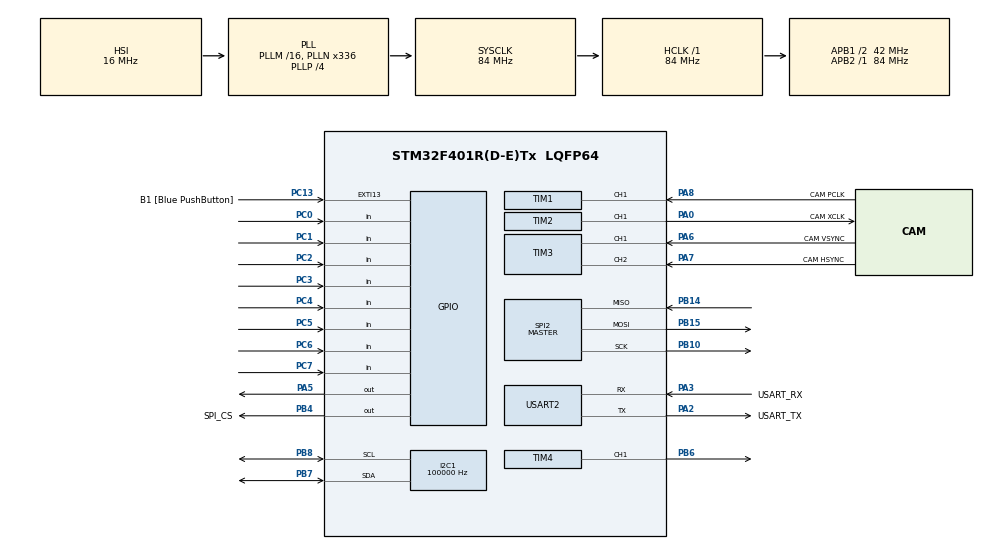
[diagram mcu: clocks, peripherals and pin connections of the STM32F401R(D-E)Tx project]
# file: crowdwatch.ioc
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Mcu.Family=STM32F4
PA2.GPIO_PuPd=GPIO_NOPULL
RCC.CortexFreq_Value=84000000
SPI2.VirtualType=VM_MASTER
PB10.Mode=Full_Duplex_Master
PA14.GPIO_Label=TCK
PA3.GPIO_PuPd=GPIO_NOPULL
PA2.GPIO_Speed=GPIO_SPEED_FREQ_LOW
Dma.TIM1_CH1.0.MemDataAlignment=DMA_MDATAALIGN_BYTE
PA6.GPIO_Label=CAM VSYNC
PA3.GPIO_Speed=GPIO_SPEED_FREQ_LOW
PB15.Signal=SPI2_MOSI
RCC.SYSCLKSource=RCC_SYSCLKSOURCE_PLLCLK
ProjectManager.StackSize=0x400
Dma.TIM1_CH1.0.MemInc=DMA_MINC_ENABLE
VP_TIM1_VS_ControllerModeReset.Mode=Reset Mode
PH0\ -\ OSC_IN.Signal=RCC_OSC_IN
I2C1.ClockSpeed=100000
RCC.HCLKFreq_Value=84000000
RCC.APB2TimFreq_Value=84000000
PB6.Signal=S_TIM4_CH1
PC7.Signal=GPIO_Input
PC3.Signal=GPIO_Input
VP_TIM3_VS_ControllerModeClock.Mode=Clock Mode
RCC.AHBFreq_Value=84000000
SPI2.BaudRatePrescaler=SPI_BAUDRATEPRESCALER_128
RCC.HSE_VALUE=8000000
TIM3.Channel-Input_Capture1_from_TI1=TIM_CHANNEL_1
PC13-ANTI_TAMP.Signal=GPXTI13
PC14-OSC32_IN.Mode=LSE-External-Oscillator
PA14.Mode=Serial_Wire
PB14.Mode=Full_Duplex_Master
PB7.Signal=I2C1_SDA
PA8.Signal=S_TIM1_CH1
TIM2.Channel-PWM\ Generation1\ CH1=TIM_CHANNEL_1
SH.S_TIM3_CH1.0=TIM3_CH1,Input_Capture1_from_TI1
TIM4.Period=255
VP_TIM3_VS_ClockSourceITR.Mode=TriggerSource_ITR0
Dma.TIM1_CH1.0.FIFOThreshold=DMA_FIFO_THRESHOLD_FULL
VP_TIM1_VS_ClockSourceINT.Mode=Internal
Mcu.Package=LQFP64
PA6.Signal=S_TIM3_CH1
SPI2.Mode=SPI_MODE_MASTER
USART2.VirtualMode=VM_ASYNC
PA2.GPIO_Label=USART_TX
SH.S_TIM4_CH1.0=TIM4_CH1,PWM Generation1 CH1
RCC.APB1TimFreq_Value=84000000
SPI2.Direction=SPI_DIRECTION_2LINES
PC5.Signal=GPIO_Input
Dma.Request0=TIM1_CH1
PB4.Signal=GPIO_Output
PA3.Signal=USART2_RX
PA2.GPIO_Mode=GPIO_MODE_AF_PP
PB3.GPIO_Label=SWO
TIM4.Channel-PWM\ Generation1\ CH1=TIM_CHANNEL_1
PC15-OSC32_OUT.Mode=LSE-External-Oscillator
TIM3.Channel-Input_Capture2_from_TI2=TIM_CHANNEL_2
PC13-ANTI_TAMP.GPIO_PuPd=GPIO_NOPULL
PC13-ANTI_TAMP.GPIO_Label=B1 [Blue PushButton]
PH1\ -\ OSC_OUT.Mode=HSE-External-Clock-Source
PC2.Signal=GPIO_Input
PC4.Signal=GPIO_Input
PC6.Signal=GPIO_Input
Dma.TIM1_CH1.0.FIFOMode=DMA_FIFOMODE_ENABLE
NVIC.DMA2_Stream1_IRQn=true\:0\:0\:false\:false\:true\:false\:true
PC0.Signal=GPIO_Input
RCC.APB1CLKDivider=RCC_HCLK_DIV2
PC14-OSC32_IN.Signal=RCC_OSC32_IN
Dma.TIM1_CH1.0.PeriphDataAlignment=DMA_PDATAALIGN_BYTE
Dma.TIM1_CH1.0.Priority=DMA_PRIORITY_VERY_HIGH
PA0-WKUP.GPIO_Label=CAM XCLK
PA0-WKUP.Signal=S_TIM2_CH1_ETR
TIM2.Pulse-PWM\ Generation1\ CH1=4
Dma.TIM1_CH1.0.PeriphInc=DMA_PINC_DISABLE
PA3.Mode=Asynchronous
PA13.Signal=SYS_JTMS-SWDIO
PH0\ -\ OSC_IN.Mode=HSE-External-Clock-Source
Dma.TIM1_CH1.0.Mode=DMA_CIRCULAR
PA8.GPIO_Label=CAM PCLK
SH.S_TIM1_CH1.0=TIM1_CH1,TriggerSource_TI1FP1
SH.S_TIM1_CH1.1=TIM1_CH1,Input_Capture1_from_TI1
ProjectManager.TargetToolchain=STM32CubeIDE
Dma.TIM1_CH1.0.PeriphBurst=DMA_PBURST_SINGLE
I2C1.I2C_Mode=I2C_Standard
PA3.GPIO_Mode=GPIO_MODE_AF_PP
PC15-OSC32_OUT.Signal=RCC_OSC32_OUT
PB10.Signal=SPI2_SCK
PB14.Signal=SPI2_MISO
PA5.Signal=GPIO_Output
SH.S_TIM3_CH2.0=TIM3_CH2,Input_Capture2_from_TI2
PH1\ -\ OSC_OUT.Signal=RCC_OSC_OUT
board=NUCLEO-F401RE
RCC.VCOOutputFreq_Value=336000000
PB15.Mode=Full_Duplex_Master
NVIC.TIM3_IRQn=true\:0\:0\:false\:false\:true\:true\:true
RCC.APB2Freq_Value=84000000
PB4.GPIO_Label=SPI_CS
TIM3.ICPolarity_CH2=TIM_INPUTCHANNELPOLARITY_FALLING
TIM3.ICPolarity_CH1=TIM_INPUTCHANNELPOLARITY_BOTHEDGE
TIM2.Period=7
PA13.Mode=Serial_Wire
Mcu.Name=STM32F401R(D-E)Tx
PA2.Signal=USART2_TX
PA13.GPIO_Label=TMS
Dma.TIM1_CH1.0.Direction=DMA_PERIPH_TO_MEMORY
RCC.48MHZClocksFreq_Value=48000000
PB3.Signal=SYS_JTDO-SWO
RCC.SYSCLKFreq_VALUE=84000000
Dma.TIM1_CH1.0.Instance=DMA2_Stream1
PA7.GPIO_Label=CAM HSYNC
TIM1.Channel-Input_Capture1_from_TI1=TIM_CHANNEL_1
PC13-ANTI_TAMP.GPIO_ModeDefaultEXTI=GPIO_MODE_IT_FALLING
Dma.TIM1_CH1.0.MemBurst=DMA_MBURST_INC16
PB7.Mode=I2C
SH.S_TIM2_CH1_ETR.0=TIM2_CH1,PWM Generation1 CH1
PA14.Signal=SYS_JTCK-SWCLK
ProjectManager.HeapSize=0x200
RCC.HSI_VALUE=16000000
VP_TIM4_VS_ClockSourceINT.Mode=Internal
RCC.PLLP=RCC_PLLP_DIV4
RCC.PLLQ=7
NVIC.PriorityGroup=NVIC_PRIORITYGROUP_0
PB8.Mode=I2C
RCC.PLLN=336
PA2.Mode=Asynchronous
PB8.Signal=I2C1_SCL
RCC.APB1Freq_Value=42000000
PC1.Signal=GPIO_Input
TIM1.TIM_MasterSlaveMode=TIM_MASTERSLAVEMODE_ENABLE
PA3.GPIO_Label=USART_RX
PA7.Signal=S_TIM3_CH2

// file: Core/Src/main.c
/* USER CODE BEGIN Header */
/**
  ******************************************************************************
  * @file           : main.c
  * @brief          : Main program body
  ******************************************************************************
  * @attention
  *
  * <h2><center>&copy; Copyright (c) 2021 STMicroelectronics.
  * All rights reserved.</center></h2>
  *
  * This software component is licensed by ST under BSD 3-Clause license,
  * the "License"; You may not use this file except in compliance with the
  * License. You may obtain a copy of the License at:
  *                        opensource.org/licenses/BSD-3-Clause
  *
  ******************************************************************************
  */
/* USER CODE END Header */
#include "main.h"

/* USER CODE BEGIN Includes */

#include "cwsys/cwsys.h"

/* USER CODE END Includes */

I2C_HandleTypeDef hi2c1;

SPI_HandleTypeDef hspi2;

TIM_HandleTypeDef htim1;
TIM_HandleTypeDef htim2;
TIM_HandleTypeDef htim3;
TIM_HandleTypeDef htim4;
DMA_HandleTypeDef hdma_tim1_ch1;

UART_HandleTypeDef huart2;

void SystemClock_Config(void);
static void MX_GPIO_Init(void);
static void MX_DMA_Init(void);
static void MX_USART2_UART_Init(void);
static void MX_I2C1_Init(void);
static void MX_TIM1_Init(void);
static void MX_TIM2_Init(void);
static void MX_TIM3_Init(void);
static void MX_SPI2_Init(void);
static void MX_TIM4_Init(void);

int main(void)
{

  /* MCU Configuration--------------------------------------------------------*/

  /* Reset of all peripherals, Initializes the Flash interface and the Systick. */
  HAL_Init();

  /* Configure the system clock */
  SystemClock_Config();

  /* Initialize all configured peripherals */
  MX_GPIO_Init();
  MX_DMA_Init();
  MX_USART2_UART_Init();
  MX_I2C1_Init();
  MX_TIM1_Init();
  MX_TIM2_Init();
  MX_TIM3_Init();
  MX_SPI2_Init();
  MX_TIM4_Init();
  /* USER CODE BEGIN 2 */

  // Configure and run CrowdWatch
  struct cwsys_init_params cwsys_param = {
		  .infoSerial = &huart2,
		  .cameraParams = {
				  .tim1Sync = &htim1,
				  .tim3Sync = &htim3,
				  .camClkPwm = &htim2,
				  .pixdma = &hdma_tim1_ch1,
				  .pixDataGPIOIdr = &GPIOC->IDR,
				  .sccb = &hi2c1,
		  },
		  .espSpi = &hspi2,
  };
  cwsys(cwsys_param);
  /* USER CODE END 2 */

  /* Infinite loop */
  while (1)
  {

  }
}

void SystemClock_Config(void)
{
  RCC_OscInitTypeDef RCC_OscInitStruct = {0};
  RCC_ClkInitTypeDef RCC_ClkInitStruct = {0};

  /** Configure the main internal regulator output voltage
  */
  __HAL_RCC_PWR_CLK_ENABLE();
  __HAL_PWR_VOLTAGESCALING_CONFIG(PWR_REGULATOR_VOLTAGE_SCALE2);
  /** Initializes the RCC Oscillators according to the specified parameters
  * in the RCC_OscInitTypeDef structure.
  */
  RCC_OscInitStruct.OscillatorType = RCC_OSCILLATORTYPE_HSI;
  RCC_OscInitStruct.HSIState = RCC_HSI_ON;
  RCC_OscInitStruct.HSICalibrationValue = RCC_HSICALIBRATION_DEFAULT;
  RCC_OscInitStruct.PLL.PLLState = RCC_PLL_ON;
  RCC_OscInitStruct.PLL.PLLSource = RCC_PLLSOURCE_HSI;
  RCC_OscInitStruct.PLL.PLLM = 16;
  RCC_OscInitStruct.PLL.PLLN = 336;
  RCC_OscInitStruct.PLL.PLLP = RCC_PLLP_DIV4;
  RCC_OscInitStruct.PLL.PLLQ = 7;
  if (HAL_RCC_OscConfig(&RCC_OscInitStruct) != HAL_OK)
  {
    Error_Handler();
  }
  /** Initializes the CPU, AHB and APB buses clocks
  */
  RCC_ClkInitStruct.ClockType = RCC_CLOCKTYPE_HCLK|RCC_CLOCKTYPE_SYSCLK
                              |RCC_CLOCKTYPE_PCLK1|RCC_CLOCKTYPE_PCLK2;
  RCC_ClkInitStruct.SYSCLKSource = RCC_SYSCLKSOURCE_PLLCLK;
  RCC_ClkInitStruct.AHBCLKDivider = RCC_SYSCLK_DIV1;
  RCC_ClkInitStruct.APB1CLKDivider = RCC_HCLK_DIV2;
  RCC_ClkInitStruct.APB2CLKDivider = RCC_HCLK_DIV1;

  if (HAL_RCC_ClockConfig(&RCC_ClkInitStruct, FLASH_LATENCY_2) != HAL_OK)
  {
    Error_Handler();
  }
}

static void MX_I2C1_Init(void)
{

  hi2c1.Instance = I2C1;
  hi2c1.Init.ClockSpeed = 100000;
  hi2c1.Init.DutyCycle = I2C_DUTYCYCLE_2;
  hi2c1.Init.OwnAddress1 = 0;
  hi2c1.Init.AddressingMode = I2C_ADDRESSINGMODE_7BIT;
  hi2c1.Init.DualAddressMode = I2C_DUALADDRESS_DISABLE;
  hi2c1.Init.OwnAddress2 = 0;
  hi2c1.Init.GeneralCallMode = I2C_GENERALCALL_DISABLE;
  hi2c1.Init.NoStretchMode = I2C_NOSTRETCH_DISABLE;
  if (HAL_I2C_Init(&hi2c1) != HAL_OK)
  {
    Error_Handler();
  }

}

static void MX_SPI2_Init(void)
{

  /* SPI2 parameter configuration*/
  hspi2.Instance = SPI2;
  hspi2.Init.Mode = SPI_MODE_MASTER;
  hspi2.Init.Direction = SPI_DIRECTION_2LINES;
  hspi2.Init.DataSize = SPI_DATASIZE_8BIT;
  hspi2.Init.CLKPolarity = SPI_POLARITY_LOW;
  hspi2.Init.CLKPhase = SPI_PHASE_1EDGE;
  hspi2.Init.NSS = SPI_NSS_SOFT;
  hspi2.Init.BaudRatePrescaler = SPI_BAUDRATEPRESCALER_256;
  hspi2.Init.FirstBit = SPI_FIRSTBIT_MSB;
  hspi2.Init.TIMode = SPI_TIMODE_DISABLE;
  hspi2.Init.CRCCalculation = SPI_CRCCALCULATION_DISABLE;
  hspi2.Init.CRCPolynomial = 10;
  if (HAL_SPI_Init(&hspi2) != HAL_OK)
  {
    Error_Handler();
  }

}

static void MX_TIM1_Init(void)
{

  TIM_ClockConfigTypeDef sClockSourceConfig = {0};
  TIM_SlaveConfigTypeDef sSlaveConfig = {0};
  TIM_MasterConfigTypeDef sMasterConfig = {0};
  TIM_IC_InitTypeDef sConfigIC = {0};

  htim1.Instance = TIM1;
  htim1.Init.Prescaler = 0;
  htim1.Init.CounterMode = TIM_COUNTERMODE_UP;
  htim1.Init.Period = 65535;
  htim1.Init.ClockDivision = TIM_CLOCKDIVISION_DIV1;
  htim1.Init.RepetitionCounter = 0;
  htim1.Init.AutoReloadPreload = TIM_AUTORELOAD_PRELOAD_DISABLE;
  if (HAL_TIM_Base_Init(&htim1) != HAL_OK)
  {
    Error_Handler();
  }
  sClockSourceConfig.ClockSource = TIM_CLOCKSOURCE_INTERNAL;
  if (HAL_TIM_ConfigClockSource(&htim1, &sClockSourceConfig) != HAL_OK)
  {
    Error_Handler();
  }
  if (HAL_TIM_IC_Init(&htim1) != HAL_OK)
  {
    Error_Handler();
  }
  sSlaveConfig.SlaveMode = TIM_SLAVEMODE_RESET;
  sSlaveConfig.InputTrigger = TIM_TS_TI1FP1;
  sSlaveConfig.TriggerPolarity = TIM_INPUTCHANNELPOLARITY_RISING;
  sSlaveConfig.TriggerFilter = 0;
  if (HAL_TIM_SlaveConfigSynchro(&htim1, &sSlaveConfig) != HAL_OK)
  {
    Error_Handler();
  }
  sMasterConfig.MasterOutputTrigger = TIM_TRGO_RESET;
  sMasterConfig.MasterSlaveMode = TIM_MASTERSLAVEMODE_ENABLE;
  if (HAL_TIMEx_MasterConfigSynchronization(&htim1, &sMasterConfig) != HAL_OK)
  {
    Error_Handler();
  }
  sConfigIC.ICPolarity = TIM_INPUTCHANNELPOLARITY_RISING;
  sConfigIC.ICSelection = TIM_ICSELECTION_DIRECTTI;
  sConfigIC.ICPrescaler = TIM_ICPSC_DIV1;
  sConfigIC.ICFilter = 0;
  if (HAL_TIM_IC_ConfigChannel(&htim1, &sConfigIC, TIM_CHANNEL_1) != HAL_OK)
  {
    Error_Handler();
  }

}

static void MX_TIM2_Init(void)
{

  TIM_MasterConfigTypeDef sMasterConfig = {0};
  TIM_OC_InitTypeDef sConfigOC = {0};

  htim2.Instance = TIM2;
  htim2.Init.Prescaler = 0;
  htim2.Init.CounterMode = TIM_COUNTERMODE_UP;
  htim2.Init.Period = 7;
  htim2.Init.ClockDivision = TIM_CLOCKDIVISION_DIV1;
  htim2.Init.AutoReloadPreload = TIM_AUTORELOAD_PRELOAD_DISABLE;
  if (HAL_TIM_PWM_Init(&htim2) != HAL_OK)
  {
    Error_Handler();
  }
  sMasterConfig.MasterOutputTrigger = TIM_TRGO_RESET;
  sMasterConfig.MasterSlaveMode = TIM_MASTERSLAVEMODE_DISABLE;
  if (HAL_TIMEx_MasterConfigSynchronization(&htim2, &sMasterConfig) != HAL_OK)
  {
    Error_Handler();
  }
  sConfigOC.OCMode = TIM_OCMODE_PWM1;
  sConfigOC.Pulse = 4;
  sConfigOC.OCPolarity = TIM_OCPOLARITY_HIGH;
  sConfigOC.OCFastMode = TIM_OCFAST_DISABLE;
  if (HAL_TIM_PWM_ConfigChannel(&htim2, &sConfigOC, TIM_CHANNEL_1) != HAL_OK)
  {
    Error_Handler();
  }
  HAL_TIM_MspPostInit(&htim2);

}

static void MX_TIM3_Init(void)
{

  TIM_SlaveConfigTypeDef sSlaveConfig = {0};
  TIM_MasterConfigTypeDef sMasterConfig = {0};
  TIM_IC_InitTypeDef sConfigIC = {0};

  htim3.Instance = TIM3;
  htim3.Init.Prescaler = 0;
  htim3.Init.CounterMode = TIM_COUNTERMODE_UP;
  htim3.Init.Period = 65535;
  htim3.Init.ClockDivision = TIM_CLOCKDIVISION_DIV1;
  htim3.Init.AutoReloadPreload = TIM_AUTORELOAD_PRELOAD_DISABLE;
  if (HAL_TIM_Base_Init(&htim3) != HAL_OK)
  {
    Error_Handler();
  }
  if (HAL_TIM_IC_Init(&htim3) != HAL_OK)
  {
    Error_Handler();
  }
  sSlaveConfig.SlaveMode = TIM_SLAVEMODE_EXTERNAL1;
  sSlaveConfig.InputTrigger = TIM_TS_ITR0;
  if (HAL_TIM_SlaveConfigSynchro(&htim3, &sSlaveConfig) != HAL_OK)
  {
    Error_Handler();
  }
  sMasterConfig.MasterOutputTrigger = TIM_TRGO_RESET;
  sMasterConfig.MasterSlaveMode = TIM_MASTERSLAVEMODE_DISABLE;
  if (HAL_TIMEx_MasterConfigSynchronization(&htim3, &sMasterConfig) != HAL_OK)
  {
    Error_Handler();
  }
  sConfigIC.ICPolarity = TIM_INPUTCHANNELPOLARITY_BOTHEDGE;
  sConfigIC.ICSelection = TIM_ICSELECTION_DIRECTTI;
  sConfigIC.ICPrescaler = TIM_ICPSC_DIV1;
  sConfigIC.ICFilter = 0;
  if (HAL_TIM_IC_ConfigChannel(&htim3, &sConfigIC, TIM_CHANNEL_1) != HAL_OK)
  {
    Error_Handler();
  }
  sConfigIC.ICPolarity = TIM_INPUTCHANNELPOLARITY_FALLING;
  if (HAL_TIM_IC_ConfigChannel(&htim3, &sConfigIC, TIM_CHANNEL_2) != HAL_OK)
  {
    Error_Handler();
  }

}

static void MX_TIM4_Init(void)
{

  TIM_ClockConfigTypeDef sClockSourceConfig = {0};
  TIM_MasterConfigTypeDef sMasterConfig = {0};
  TIM_OC_InitTypeDef sConfigOC = {0};

  htim4.Instance = TIM4;
  htim4.Init.Prescaler = 0;
  htim4.Init.CounterMode = TIM_COUNTERMODE_UP;
  htim4.Init.Period = 255;
  htim4.Init.ClockDivision = TIM_CLOCKDIVISION_DIV1;
  htim4.Init.AutoReloadPreload = TIM_AUTORELOAD_PRELOAD_DISABLE;
  if (HAL_TIM_Base_Init(&htim4) != HAL_OK)
  {
    Error_Handler();
  }
  sClockSourceConfig.ClockSource = TIM_CLOCKSOURCE_INTERNAL;
  if (HAL_TIM_ConfigClockSource(&htim4, &sClockSourceConfig) != HAL_OK)
  {
    Error_Handler();
  }
  if (HAL_TIM_PWM_Init(&htim4) != HAL_OK)
  {
    Error_Handler();
  }
  sMasterConfig.MasterOutputTrigger = TIM_TRGO_RESET;
  sMasterConfig.MasterSlaveMode = TIM_MASTERSLAVEMODE_DISABLE;
  if (HAL_TIMEx_MasterConfigSynchronization(&htim4, &sMasterConfig) != HAL_OK)
  {
    Error_Handler();
  }
  sConfigOC.OCMode = TIM_OCMODE_PWM1;
  sConfigOC.Pulse = 0;
  sConfigOC.OCPolarity = TIM_OCPOLARITY_HIGH;
  sConfigOC.OCFastMode = TIM_OCFAST_DISABLE;
  if (HAL_TIM_PWM_ConfigChannel(&htim4, &sConfigOC, TIM_CHANNEL_1) != HAL_OK)
  {
    Error_Handler();
  }
  HAL_TIM_MspPostInit(&htim4);

}

static void MX_USART2_UART_Init(void)
{

  huart2.Instance = USART2;
  huart2.Init.BaudRate = 115200;
  huart2.Init.WordLength = UART_WORDLENGTH_8B;
  huart2.Init.StopBits = UART_STOPBITS_1;
  huart2.Init.Parity = UART_PARITY_NONE;
  huart2.Init.Mode = UART_MODE_TX_RX;
  huart2.Init.HwFlowCtl = UART_HWCONTROL_NONE;
  huart2.Init.OverSampling = UART_OVERSAMPLING_16;
  if (HAL_UART_Init(&huart2) != HAL_OK)
  {
    Error_Handler();
  }

}

static void MX_DMA_Init(void)
{

  /* DMA controller clock enable */
  __HAL_RCC_DMA2_CLK_ENABLE();

  /* DMA interrupt init */
  /* DMA2_Stream1_IRQn interrupt configuration */
  HAL_NVIC_SetPriority(DMA2_Stream1_IRQn, 0, 0);
  HAL_NVIC_EnableIRQ(DMA2_Stream1_IRQn);

}

static void MX_GPIO_Init(void)
{
  GPIO_InitTypeDef GPIO_InitStruct = {0};

  /* GPIO Ports Clock Enable */
  __HAL_RCC_GPIOC_CLK_ENABLE();
  __HAL_RCC_GPIOH_CLK_ENABLE();
  __HAL_RCC_GPIOA_CLK_ENABLE();
  __HAL_RCC_GPIOB_CLK_ENABLE();

  /*Configure GPIO pin Output Level */
  HAL_GPIO_WritePin(GPIOA, GPIO_PIN_5, GPIO_PIN_RESET);

  /*Configure GPIO pin Output Level */
  HAL_GPIO_WritePin(SPI_CS_GPIO_Port, SPI_CS_Pin, GPIO_PIN_RESET);

  /*Configure GPIO pin : B1_Pin */
  GPIO_InitStruct.Pin = B1_Pin;
  GPIO_InitStruct.Mode = GPIO_MODE_IT_FALLING;
  GPIO_InitStruct.Pull = GPIO_NOPULL;
  HAL_GPIO_Init(B1_GPIO_Port, &GPIO_InitStruct);

  /*Configure GPIO pins : PC0 PC1 PC2 PC3
                           PC4 PC5 PC6 PC7 */
  GPIO_InitStruct.Pin = GPIO_PIN_0|GPIO_PIN_1|GPIO_PIN_2|GPIO_PIN_3
                          |GPIO_PIN_4|GPIO_PIN_5|GPIO_PIN_6|GPIO_PIN_7;
  GPIO_InitStruct.Mode = GPIO_MODE_INPUT;
  GPIO_InitStruct.Pull = GPIO_NOPULL;
  HAL_GPIO_Init(GPIOC, &GPIO_InitStruct);

  /*Configure GPIO pin : PA5 */
  GPIO_InitStruct.Pin = GPIO_PIN_5;
  GPIO_InitStruct.Mode = GPIO_MODE_OUTPUT_PP;
  GPIO_InitStruct.Pull = GPIO_NOPULL;
  GPIO_InitStruct.Speed = GPIO_SPEED_FREQ_LOW;
  HAL_GPIO_Init(GPIOA, &GPIO_InitStruct);

  /*Configure GPIO pin : SPI_CS_Pin */
  GPIO_InitStruct.Pin = SPI_CS_Pin;
  GPIO_InitStruct.Mode = GPIO_MODE_OUTPUT_PP;
  GPIO_InitStruct.Pull = GPIO_NOPULL;
  GPIO_InitStruct.Speed = GPIO_SPEED_FREQ_LOW;
  HAL_GPIO_Init(SPI_CS_GPIO_Port, &GPIO_InitStruct);

  /*Configure GPIO pin : SPI_BUSY_Pin */
  GPIO_InitStruct.Pin = SPI_BUSY_Pin;
  GPIO_InitStruct.Mode = GPIO_MODE_INPUT;
  GPIO_InitStruct.Pull = GPIO_NOPULL;
  HAL_GPIO_Init(SPI_BUSY_GPIO_Port, &GPIO_InitStruct);

}

void Error_Handler(void)
{
  __disable_irq();
  while (1)
  {
  }
}

/************************ (C) COPYRIGHT STMicroelectronics *****END OF FILE****/
